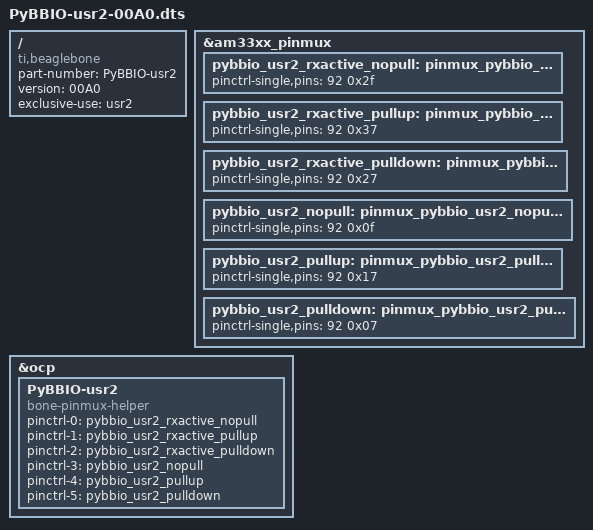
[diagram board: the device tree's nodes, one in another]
/dts-v1/;
/plugin/;

/{
  compatible = "ti,beaglebone", "ti,beaglebone-black";

  part-number = "PyBBIO-usr2";
  version = "00A0";

  /* state the resources this cape uses */
  exclusive-use =
    /* the pin header uses */

    /* the hardware IP uses */
    "usr2";

  fragment@0 {
    target = <&am33xx_pinmux>;
    __overlay__ {

      pybbio_usr2_rxactive_nopull: pinmux_pybbio_usr2_rxactive_nopull {
        pinctrl-single,pins = <
          92 0x2f  /* gpmc_a7 - rx active | no pull | MODE7 (usr2) */
        >;
      };
      pybbio_usr2_rxactive_pullup: pinmux_pybbio_usr2_rxactive_pullup {
        pinctrl-single,pins = <
          92 0x37  /* gpmc_a7 - rx active | pull up | MODE7 (usr2) */
        >;
      };
      pybbio_usr2_rxactive_pulldown: pinmux_pybbio_usr2_rxactive_pulldown {
        pinctrl-single,pins = <
          92 0x27  /* gpmc_a7 - rx active | pull down | MODE7 (usr2) */
        >;
      };
      
      pybbio_usr2_nopull: pinmux_pybbio_usr2_nopull {
        pinctrl-single,pins = <
          92 0x0f  /* gpmc_a7 - rx active | no pull | MODE7 (usr2) */
        >;
      };
      pybbio_usr2_pullup: pinmux_pybbio_usr2_pullup {
        pinctrl-single,pins = <
          92 0x17  /* gpmc_a7 - rx active | pull up | MODE7 (usr2) */
        >;
      };
      pybbio_usr2_pulldown: pinmux_pybbio_usr2_pulldown {
        pinctrl-single,pins = <
          92 0x07  /* gpmc_a7 - rx active | pull down | MODE7 (usr2) */
        >;
      };
      
    };
  };

  fragment@1 {
    target = <&ocp>; /* On-Chip Peripherals */
    __overlay__ {
      PyBBIO-usr2 {
        compatible = "bone-pinmux-helper"; /* Use the pinmux helper */
        status="okay";
        /* Define custom names for indexes in pinctrl array: */ 
        pinctrl-names = "mode_0b00101111", "mode_0b00110111", "mode_0b00100111",
                        "mode_0b00001111", "mode_0b00010111", "mode_0b00000111";
        /* Set the elements of the pinctrl array to the pinmux overlays
           defined above: */
        pinctrl-0 = <&pybbio_usr2_rxactive_nopull>; 
        pinctrl-1 = <&pybbio_usr2_rxactive_pullup>; 
        pinctrl-2 = <&pybbio_usr2_rxactive_pulldown>;
        pinctrl-3 = <&pybbio_usr2_nopull>; 
        pinctrl-4 = <&pybbio_usr2_pullup>; 
        pinctrl-5 = <&pybbio_usr2_pulldown>;
      };
    };
  };
};
